# pse84_a0 register map
Vendor: Infineon Technologies; Series: PSE84_A0; File version: 1.0
CPU: CM33 r0p1, little endian, MPU, FPU, VTOR, 3 interrupt priority bits
Registers are 32-bit, read-write, reset 0x0 unless marked. A register's access mark holds for its fields unless they carry their own. Offsets are from the block's base; [hi:lo] are bit positions; lines under a group give offsets from that group; {n}, {i} and the like mark numbered series; 'fields as' and 'values as' point back to an identical list; <NAME> marks a mode.

## USBHS (part 5 of 7) — Regmap for both Subsystem and Controller IP
Base 0x44900000
0x00 DWC_OTG_INTREG group — Internal register map
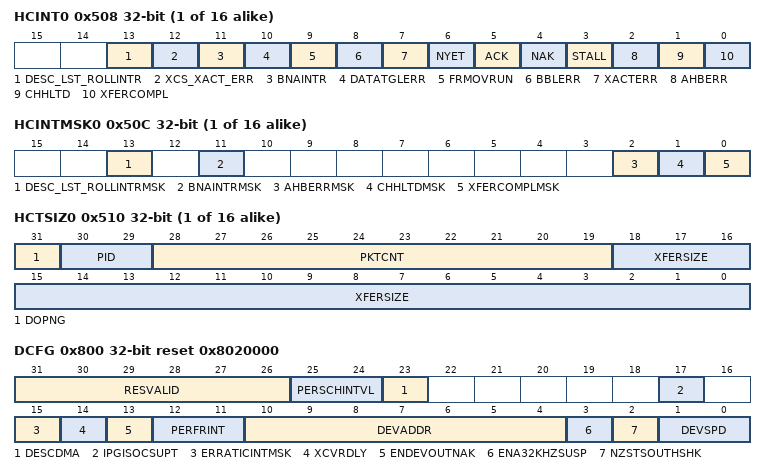
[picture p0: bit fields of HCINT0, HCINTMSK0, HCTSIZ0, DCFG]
  {0x508+0x20*j} HCINT{j} (j=0..15) — This register indicates the status of a channel with respect to USB- and AHB-related events. It is shown in the 'Interrupt Hierarchy' figure in the databook. The application must read this register when the Host Channels Interrupt bit of the Core Interrupt register (GINTSTS.HChInt) is set. Before the application can read this register, it must first read the Host All Channels Interrupt (HAINT) register to get the exact channel number for the Host Channel-n Interrupt register. The application must clear the appropriate bit in this register to clear the corresponding bits in the HAINT and GINTSTS registers.
    [13] DESC_LST_ROLLINTR
      1=ACTIVE (Descriptor rollover interrupt); 0=INACTIVE (No Descriptor rollover interrupt)
    [12] XCS_XACT_ERR
      1=ACTIVE (Excessive Transaction Error); 0=INACTIVE (No Excessive Transaction Error)
    [11] BNAINTR
      1=ACTIVE (BNA Interrupt); 0=INACTIVE (No BNA Interrupt)
    [10] DATATGLERR — Data Toggle Error (DataTglErr).This bit can be set only by the core and the application should write 1 to clear it.In Scatter/Gather DMA mode, the interrupt due to this bit is masked in the core.
      1=ACTIVE (Data Toggle Error); 0=INACTIVE (No Data Toggle Error)
    [9] FRMOVRUN — Frame Overrun (FrmOvrun). In Scatter/Gather DMA mode, the interrupt due to this bit is masked in the core. This bit can be set only by the core and the application should write 1 to clear it.
      1=ACTIVE (Frame Overrun); 0=INACTIVE (No Frame Overrun)
    [8] BBLERR — Babble Error (BblErr) In Scatter/Gather DMA mode, the interrupt due to this bit is masked in the core. This bit can be set only by the core and the application should write 1 to clear it.
      1=ACTIVE (Babble Error); 0=INACTIVE (No Babble Error)
    [7] XACTERR — Transaction Error (XactErr) Indicates one of the following errors occurred on the USB. - CRC check failure - Timeout - Bit stuff error - False EOP In Scatter/Gather DMA mode, the interrupt due to this bit is masked in the core.This bit can be set only by the core and the application should write 1 to clear it.
      1=ACTIVE (Transaction Error); 0=INACTIVE (No Transaction Error)
    [6] NYET — NYET Response Received Interrupt (NYET) In Scatter/Gather DMA mode, the interrupt due to this bit is masked in the core.This bit can be set only by the core and the application should write 1 to clear it.
      1=ACTIVE (NYET Response Received Interrupt); 0=INACTIVE (No NYET Response Received Interrupt)
    [5] ACK — ACK Response Received/Transmitted Interrupt (ACK) In Scatter/Gather DMA mode, the interrupt due to this bit is masked in the core.This bit can be set only by the core and the application should write 1 to clear it.
      1=ACTIVE (ACK Response Received or Transmitted Interrup); 0=INACTIVE (No ACK Response Received or Transmitted Interrupt)
    [4] NAK — NAK Response Received Interrupt (NAK) In Scatter/Gather DMA mode, the interrupt due to this bit is masked in the core.This bit can be set only by the core and the application should write 1 to clear it.
      1=ACTIVE (NAK Response Received Interrupt); 0=INACTIVE (No NAK Response Received Interrupt)
    [3] STALL — STALL Response Received Interrupt (STALL) In Scatter/Gather DMA mode, the interrupt due to this bit is masked in the core.This bit can be set only by the core and the application should write 1 to clear it.
      1=ACTIVE (Stall Response Received Interrupt); 0=INACTIVE (No Stall Response Received Interrupt)
    [2] AHBERR — AHB Error (AHBErr) This is generated only in Internal DMA mode when there is an AHB error during AHB read/write. The application can read the corresponding channel's DMA address register to get the error address. For details, see 'AHB Error Handling' in the Programming Guide.
      1=ACTIVE (AHB error during AHB read/write); 0=INACTIVE (No AHB error)
    [1] CHHLTD — Channel Halted (ChHltd) In non Scatter/Gather DMA mode, it indicates the transfer completed abnormally either because of any USB transaction error or in response to disable request by the application or because of a completed transfer. In Scatter/gather DMA mode, this indicates that transfer completed due to any of the following - EOL being set in descriptor - AHB error - Excessive transaction errors - Babble - Stall
      1=ACTIVE (Channel Halted); 0=INACTIVE (Channel not halted)
    [0] XFERCOMPL — Transfer Completed (XferCompl) Transfer completed normally without any errors.This bit can be set only by the core and the application should write 1 to clear it. - For Scatter/Gather DMA mode, it indicates that current descriptor processing got completed with IOC bit set in its descriptor. - In non Scatter/Gather DMA mode, it indicates that Transfer completed normally without any errors.
      1=ACTIVE (Transfer completed normally without any errors); 0=INACTIVE (Transfer in progress or No Active Transfer)
  {0x50C+0x20*j} HCINTMSK{j} (j=0..15) — This register reflects the mask for each channel status described in the previous section.
    [13] DESC_LST_ROLLINTRMSK — Descriptor List rollover interrupt Mask register(DESC_LST_ROLLIntrMsk) This bit is valid only when Scatter/Gather DMA mode is enabled.
      0=MASK (Descriptor Rollover Interrupt Mask); 1=NOMASK (Descriptor Rollover Interrupt not masked)
    [11] BNAINTRMSK — BNA (Buffer Not Available) Interrupt mask register (BNAIntrMsk) This bit is valid only when Scatter/Gather DMA mode is enabled.
      0=MASK (BNA Interrupt Masked); 1=NOMASK (BNA Interrupt not masked)
    [2] AHBERRMSK — AHB Error Mask (AHBErrMsk) In scatter/gather DMA mode for host, interrupts will not be generated due to the corresponding bits set in HCINTn.
      0=MASK (AHB Error Mask); 1=NOMASK (No AHB Error Mask)
    [1] CHHLTDMSK — Channel Halted Mask (ChHltdMsk)
      0=MASK (Channel Halted Mask); 1=NOMASK (No Channel Halted Mask)
    [0] XFERCOMPLMSK — Transfer Completed Mask (XferComplMsk)
      0=MASK (Transfer Completed Mask); 1=NOMASK (No Transfer Completed Mask)
  {0x510+0x20*j} HCTSIZ{j} (j=0..15) — This register reflects the transfer size for the Host Channel.
    [31] DOPNG — Do Ping (DoPng) This bit is used only for OUT transfers. Setting this field to 1 directs the host to do PING protocol. Note: Do not set this bit for IN transfers. If this bit is set for for IN transfers it disables the channel.
      0=NOPING (No ping protocol); 1=PING (Ping protocol)
    [30:29] PID — PID (Pid) The application programs this field with the type of PID to use for the initial transaction. The host maintains this field for the rest of the transfer. - 2'b00: DATA0 - 2'b01: DATA2 - 2'b10: DATA1 - 2'b11: MDATA (non-control)/SETUP (control)
      0=DATA0; 2=DATA1; 1=DATA2; 3=MDATA (MDATA (non-control)/SETUP (control))
    [28:19] PKTCNT
    [18:0] XFERSIZE
  {0x514+0x20*j} HCDMA{j} (j=0..15) — This register is used by the OTG host in the internal DMA mode to maintain the current buffer pointer for IN/OUT transactions. The starting DMA address must be DWORD-aligned.
    [31:0] DMAADDR
  {0x51C+0x20*j} HCDMAB{j} ro (j=0..15) — This register is present only in case of Scatter/Gather DMA. It is implemented in RAM instead of flop-based implementation. This register holds the current buffer address.
    [31:0] HCDMAB
  0x800 DCFG reset 0x8020000 — This register configures the core in Device mode after power-on or after certain control commands or enumeration. Do not make changes to this register after initial programming.
    [31:26] RESVALID — Resume Validation Period (ResValid) This field is effective only when DCFG.Ena32KHzSusp is set. It controls the resume period when the core resumes from suspend. The core counts for ResValid number of clock cycles to detect a valid resume when this bit is set
    [25:24] PERSCHINTVL
      0=MF25 (25 percent of <ct:DWC_DESIGN_ID==1>frame</ct><ct:DWC_DESIGN_ID!=1>(micro)Frame</ct>); 1=MF50 (50 percent of <ct:DWC_DESIGN_ID==1>frame</ct><ct:DWC_DESIGN_ID!=1>(micro)Frame</ct>); 2=MF75 (75 percent of <ct:DWC_DESIGN_ID==1>frame</ct><ct:DWC_DESIGN_ID!=1>(micro)Frame</ct>); 3=RSVDPerSchIntvlDCFG (N/A)
    [23] DESCDMA — Enable Scatter/gather DMA in device mode (DescDMA). When the Scatter/Gather DMA option selected during configuration of the RTL, the application can Set this bit during initialization to enable the Scatter/Gather DMA operation. Note: This bit must be modified only once after a reset. The following combinations are available for programming: - GAHBCFG.DMAEn=0,DCFG.DescDMA=0 => Slave mode - GAHBCFG.DMAEn=0,DCFG.DescDMA=1 => Invalid - GAHBCFG.DMAEn=1,DCFG.DescDMA=0 => Buffered DMA mode - GAHBCFG.DMAEn=1,DCFG.DescDMA=1 => Scatter/Gather DMA mode
      0=DISABLED (Disable Scatter/Gather DMA); 1=ENABLED (Enable Scatter/Gather DMA)
    [17] IPGISOCSUPT — Worst-Case Inter-Packet Gap ISOC OUT Support (ipgisocSupt) This bit indicates that the controller supports the worst-case scenario of Rx followed by Rx Inter-Packet Gap (IPG) (32 bit times) as per the UTMI Specification for any token following an ISOC OUT token. Without this support, when any token follows an ISOC OUT token with the worst-case IPG, the controller will not detect the followed token. The worst-case IPG of the controller without this support depends on the AHB and PHY clock frequency.
      0=DISABLED (Worst-Case Inter-Packet Gap ISOC OUT Support is disabled); 1=ENABLED (Worst-Case Inter-Packet Gap ISOC OUT Support is enabled)
    [15] ERRATICINTMSK — Erratic Error Interrupt Mask
      1=MASK (Mask early suspend interrupt on erratic error); 0=NOMASK (Early suspend interrupt is generated on erratic error)
    [14] XCVRDLY — XCVRDLY Enables or disables delay between xcvr_sel and txvalid during device chirp
      0=DISABLE (No delay between xcvr_sel and txvalid during Device chirp); 1=ENABLE (Enable delay between xcvr_sel and txvalid during Device chirp)
    [13] ENDEVOUTNAK — Enable Device OUT NAK (EnDevOutNak) This bit enables setting NAK for Bulk OUT endpoints after the transfer is completed for Device mode Descriptor DMA - 1'b0 : The core does not set NAK after Bulk OUT transfer complete - 1'b1 : The core sets NAK after Bulk OUT transfer complete This bit is one time programmable after reset like any other DCFG register bits.
      0=DISABLED (The core does not set NAK after Bulk OUT transfer complete); 1=ENABLED (The core sets NAK after Bulk OUT transfer complete)
    [12:11] PERFRINT — Periodic Frame Interval (PerFrInt) Indicates the time within a (micro)Frame at which the application must be notified using the End Of Periodic Frame Interrupt. This can be used to determine If all the isochronous traffic for that (micro)Frame is complete. - 2'b00: 80 percent of the (micro)Frame interval - 2'b01: 85 percent of the (micro)Frame interval - 2'b10: 90 percent of the (micro)Frame interval - 2'b11: 95 percent of the (micro)Frame interval
      0=EOPF80 (80 percent of the <ct:DWC_DESIGN_ID==1>frame</ct><ct:DWC_DESIGN_ID!=1>(micro)Frame</ct> interval); 1=EOPF85 (85 percent of the <ct:DWC_DESIGN_ID==1>frame</ct><ct:DWC_DESIGN_ID!=1>(micro)Frame</ct> interval); 2=EOPF90 (90 percent of the <ct:DWC_DESIGN_ID==1>frame</ct><ct:DWC_DESIGN_ID!=1>(micro)Frame</ct> interval); 3=EOPF95 (95 percent of the <ct:DWC_DESIGN_ID==1>frame</ct><ct:DWC_DESIGN_ID!=1>(micro)Frame</ct> interval)
    [10:4] DEVADDR — Device Address (DevAddr) The application must program this field after every SetAddress control command.
    [3] ENA32KHZSUSP — Enable 32 KHz Suspend mode (Ena32KHzSusp) This bit can be set only if FS PHY interface is selected. Otherwise, this bit needs to be set to zero. If FS PHY interface is chosen and this bit is set, the PHY clock during Suspend must be switched from 48 MHz to 32 KHz.
      0=DISABLED (USB 1.1 Full-Speed Serial Transceiver not selected); 1=ENABLED (USB 1.1 Full-Speed Serial Transceiver Interface selected)
    [2] NZSTSOUTHSHK — Non-Zero-Length Status OUT Handshake (NZStsOUTHShk) The application can use this field to select the handshake the core sends on receiving a nonzero-length data packet during the OUT transaction of a control transfer's Status stage. - 1'b1: Send a STALL handshake on a nonzero-length status OUT transaction and do not send the received OUT packet to the application. - 1'b0: Send the received OUT packet to the application (zerolength or nonzero-length) and send a handshake based on the NAK and STALL bits for the endpoint in the Device Endpoint Control register.
      0=SENDOUT (Send the received OUT packet to the application (zero-length or non-zero length) and send a handshake based on NAK and STALL bits for the endpoint in the Devce Endpoint Control Register); 1=SENDSTALL (Send a STALL handshake on a nonzero-length status OUT transaction and do not send the received OUT packet to the application)
    [1:0] DEVSPD — Device Speed (DevSpd) Indicates the speed at which the application requires the core to enumerate, or the maximum speed the application can support. However, the actual bus speed is determined only after the connect sequence is completed, and is based on the speed of the USB host to which the core is connected.
      3=USBFS1148 (Full speed USB 1.1 transceiver clock is 48 MHz); 1=USBFS20 (Full speed USB 2.0 PHY clock is 30 MHz or 60 MHz); 0=USBHS20 (High speed USB 2.0 PHY clock is 30 MHz or 60 MHz); 2=USBLS116 (Low speed USB 1.1 transceiver clock is 6 MHz)
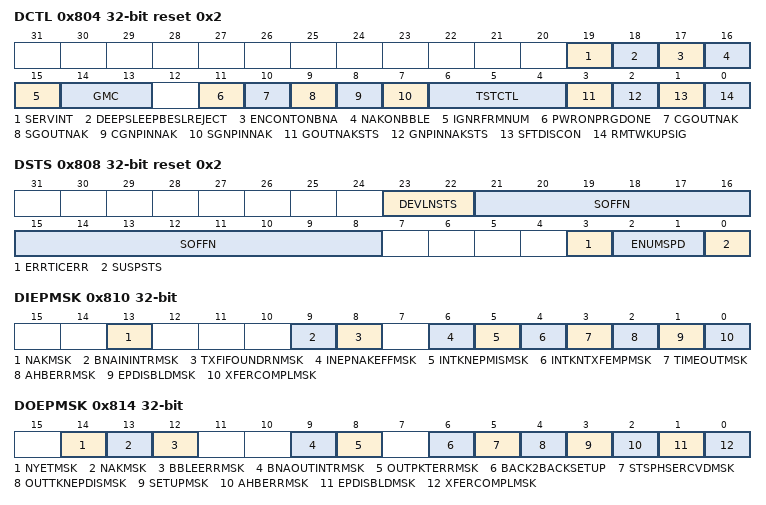
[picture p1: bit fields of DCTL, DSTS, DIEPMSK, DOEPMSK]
  0x804 DCTL reset 0x2 — This register is used to control the characteristics of the Device controller.
    [19] SERVINT — Service Interval based scheduling for Isochronous IN Endpoints This field is used to enable service interval based scheduling feature for ISOC IN EPs. Note: This bit is applicable only in device mode and when Scatter/Gather DMA mode is used. This feature should not be enabled along with DCTL.IgnrFrmNum. Scatter/Gather DMA Mode (GAHBCFG.DMAEn=1,DCFG.DescDMA=1): When this bit is enabled, the frame number field in the ISOC IN descriptor structure is interpreted as the last frame of the service interval. In Scatter/Gather DMA mode, if this bit is enabled, the pending packets are flushed by the controller at the last frame of the service interval.
      0=DISABLED (The controller behavior depends on DCTL.IgnrFrmNum field.); 1=ENABLED (<ct:DWC_DESIGN_ID==0>Scatter/Gather DMA Mode: </ct>The controller can transmit the packets in any frame of the service interval.)
    [18] DEEPSLEEPBESLREJECT — DeepSleepBESLReject - 1: Deep Sleep BESL Reject feature is enabled - 0: Deep Sleep BESL Reject feature is disabled Core rejects LPM request with HIRD value greater than HIRD threshold programmed. NYET response is sent for LPM tokens with HIRD value greater than HIRD threshold. By default, the Deep Sleep BESL Reject feature is disabled.
      0=DISABLED (Deep Sleep BESL Reject feature is disabled); 1=ENABLED (Deep Sleep BESL Reject feature is enabled)
    [17] ENCONTONBNA — Enable Continue on BNA (EnContOnBNA) This bit enables the core to continue on BNA for Bulk OUT endpoints. With this feature enabled, when a Bulk OUT or INTR OUT endpoint receives a BNA interrupt the core starts processing the descriptor that caused the BNA interrupt after the endpoint re-enables the endpoint. - 1'b0: After receiving BNA interrupt,the core disables the endpoint. When the endpoint is re-enabled by the application, the core starts processing from the DOEPDMA descriptor. - 1'b1: After receiving BNA interrupt, the core disables the endpoint. When the endpoint is re-enabled by the application, the core starts processing from the descriptor that received the BNA interrupt. This bit is valid only when OTG_EN_DESC_DMA == 1'b1. It is a one-time programmable after reset bit like any other DCTL register bits.
      0=DISABLED (Core disables the endpoint after receiving BNA interrupt. When application re-enables the endpoint, core starts processing from the DOEPDMA descriptor); 1=ENABLED (Core disables the endpoint after receiving BNA interrupt. When application re-enables the endpoint, core starts processing from the descriptor that received the BNA interrupt.)
    [16] NAKONBBLE — NAK on Babble Error (NakOnBble) Set NAK automatically on babble (NakOnBble). The core sets NAK automatically for the endpoint on which babble is received.
      0=DISABLED (Disable NAK on Babble Error); 1=ENABLED (NAK on Babble Error)
    [15] IGNRFRMNUM — Ignore Frame Number Feature for Isochronous Endpoints (IgnrFrmNum) This field is also used to control the Periodic Transfer Interrupt (PTI) feature. Note: Do not program IgnrFrmNum bit to 1'b1 when the core is operating in threshold mode. Slave Mode (GAHBCFG.DMAEn=0): This bit is not valid in Slave mode and should not be programmed to 1. Scatter/Gather DMA Mode (GAHBCFG.DMAEn=1,DCFG.DescDMA=1): Note: When Scatter/Gather DMA mode is enabled this feature is not applicable to High Speed, High bandwidth transfers. When this bit is enabled, there must be only one packet per descriptor. - 0: The core transmits the packets only in the frame number in which they are intended to be transmitted. - 1: The core ignores the frame number, sending packets immediately as the packets are ready. In Scatter/Gather DMA mode, if this bit is enabled, the packets are not flushed when a ISOC IN token is received for an elapsed frame. Non-Scatter/Gather DMA Mode, that is, Buffer DMA Mode (GAHBCFG.DMAEn=1,DCFG.DescDMA=0): When Scatter/Gather DMA mode is disabled, this field is used by the application to enable Periodic Transfer Interrupt (PTI) Mode. The application can program Periodic Endpoint transfers for multiple (micro)Frames. - 0: Periodic Transfer Interrupt feature is disabled, application needs to program transfers for periodic endpoints every (micro)Frame - 1: Periodic Transfer Interrupt feature is enabled, application can program transfers for multiple (micro)Frames for periodic endpoints. In the PTI mode, the application will receive Transfer Complete Interrupt after transfers for multiple (micro)Frames are completed.
      0=DISABLED (<ct:DWC_DESIGN_ID==0>Scatter/Gather DMA Mode: </ct>The core transmits the packets only in the frame number in which they are intended to be transmitted.<ct:DWC_DESIGN_ID==0><br>Non-Scatter/Gather DMA Mode: Periodic Transfer Interrupt feature is disabled.</ct>); 1=ENABLED (<ct:DWC_DESIGN_ID==0>Scatter/Gather DMA Mode: </ct>The core ignores the frame number, sending packets immediately as the packets are ready.<ct:DWC_DESIGN_ID==0><br>Non-Scatter/Gather DMA Mode: Periodic Transfer Interrupt feature is enabled.</ct>)
    [14:13] GMC
      0=NOTVALID (Invalid); 1=ONEPACKET (1 packet); 3=THREEPACKET (3 packets); 2=TWOPACKET (2 packets)
    [11] PWRONPRGDONE — Power-On Programming Done (PWROnPrgDone) The application uses this bit to indicate that register programming is completed after a wake-up from Power Down mode.
      1=DONE (Power-On Programming Done); 0=NOTDONE (Power-On Programming not done)
    [10] CGOUTNAK wo — Clear Global OUT NAK (CGOUTNak) A write to this field clears the Global OUT NAK.
      0=DISABLED (Disable Clear Global OUT NAK); 1=ENABLED (Clear Global OUT NAK)
    [9] SGOUTNAK wo — Set Global OUT NAK (SGOUTNak) A write to this field sets the Global OUT NAK. The application uses this bit to send a NAK handshake on all OUT endpoints. The application must set the this bit only after making sure that the Global OUT NAK Effective bit in the Core Interrupt Register (GINTSTS.GOUTNakEff) is cleared.
      0=DISABLED (Disable Global OUT NAK); 1=ENABLED (Set Global OUT NAK)
    [8] CGNPINNAK wo — Clear Global Non-periodic IN NAK (CGNPInNak) A write to this field clears the Global Non-periodic IN NAK.
      0=DISABLE (Disable Global Non-periodic IN NAK); 1=ENABLE (Clear Global Non-periodic IN NAK)
    [7] SGNPINNAK wo — Set Global Non-periodic IN NAK (SGNPInNak) A write to this field sets the Global Non-periodic IN NAK.The application uses this bit to send a NAK handshake on all non-periodic IN endpoints. The core can also Set this bit when a timeout condition is detected on a non-periodic endpoint in shared FIFO operation. The application must Set this bit only after making sure that the Global IN NAK Effective bit in the Core Interrupt Register (GINTSTS.GINNakEff) is cleared
      0=DISABLE (Disable Global Non-periodic IN NAK); 1=ENABLE (Set Global Non-periodic IN NAK)
    [6:4] TSTCTL
      0=DISABLED (Test mode disabled); 5=TESTFE (Test_force_Enable); 1=TESTJ (Test_J mode); 2=TESTK (Test_K mode); 4=TESTPM (Test_Packet mode); 3=TESTSN (Test_SE0_NAK mode)
    [3] GOUTNAKSTS ro — Global OUT NAK Status (GOUTNakSts) - 1'b0: A handshake is sent based on the FIFO Status and the NAK and STALL bit settings. - 1'b1: No data is written to the RxFIFO, irrespective of space availability. Sends a NAK handshake on all packets, except on SETUP transactions. All isochronous OUT packets are dropped.
      1=ACTIVE (No data is written to the RxFIFO, irrespective of space availability. Sends a NAK handshake on all packets, except on SETUP transactions. All isochronous OUT packets are dropped.); 0=INACTIVE (A handshake is sent based on the FIFO Status and the NAK and STALL bit settings.)
    [2] GNPINNAKSTS ro — Global Non-periodic IN NAK Status (GNPINNakSts) - 1'b0: A handshake is sent out based on the data availability in the transmit FIFO. - 1'b1: A NAK handshake is sent out on all non-periodic IN endpoints, irrespective of the data availability in the transmit FIFO.
      1=ACTIVE (A NAK handshake is sent out on all non-periodic IN endpoints, irrespective of the data availability in the transmit FIFO.); 0=INACTIVE (A handshake is sent out based on the data availability in the transmit FIFO)
    [1] SFTDISCON — Soft Disconnect (SftDiscon) The application uses this bit to signal the controller to do a soft disconnect. As long as this bit is set, the host does not see that the device is connected, and the device does not receive signals on the USB. The core stays in the disconnected state until the application clears this bit. - 1'b0: Normal operation. When this bit is cleared after a soft disconnect, the core drives the phy_opmode_o signal on the UTMI+ to 2'b00, which generates a device connect event to the USB host. When the device is reconnected, the USB host restarts device enumeration. - 1'b1: The core drives the phy_opmode_o signal on the UTMI+ to 2'b01, which generates a device disconnect event to the USB host. The following is the minimum duration under various conditions for which this bit must be set for the USB host to detect a device disconnect. To accommodate clock jitter, it is recommended that the application adds some extra delay to the specified minimum duration. For high speed, if the device state is, - Suspended, the minimum duration is 1ms + 2.5us - Idle, the minimum duration is 3ms + 2.5us - Not Idle or Suspended (performing transactions), the minimum duration 125 us For full speed/low speed, if the device state is, - Suspended, the minimum duration is 1ms + 2.5us - Idle, the minimum duration is 2.5us - Not Idle or Suspended (performing transactions), the minimum duration 125 us Note: - This bit can be also used for ULPI/FS Serial interfaces. - This bit is not impacted by a soft reset.
      1=DISCONNECT (The core <ct:DWC_DESIGN_ID!=1>drives the phy_opmode_o signal on the UTMI+ to 2'b01, which </ct>generates a device disconnect event to the USB host); 0=NODISCONNECT (The core <ct:DWC_DESIGN_ID!=1>drives the phy_opmode_o signal on the UTMI+ to 2'b00, which </ct>generates a device connect event to the USB host)
    [0] RMTWKUPSIG — Remote Wakeup Signaling (RmtWkUpSig) When the application sets this bit, the core initiates remote signaling to wake up the USB host. The application must Set this bit to instruct the core to exit the Suspend state. As specified in the USB 2.0 specification, the application must clear this bit 1-15 ms after setting it. If LPM is enabled and the core is in the L1 (Sleep) state, when the application sets this bit, the core initiates L1 remote signaling to wake up the USB host. The application must set this bit to instruct the core to exit the Sleep state. As specified in the LPM specification, the hardware automatically clears this bit 50 microseconds (TL1DevDrvResume) after being set by the application. The application must not set this bit when GLPMCFG bRemoteWake from the previous LPM transaction is zero.
      0=DISABLEDRMWKUP (Core does not send Remote Wakeup Signaling); 1=ENABLERMWKUP (Core sends Remote Wakeup Signaling)
  0x808 DSTS ro reset 0x2 — This register indicates the status of the core with respect to USB-related events. It must be read on interrupts from Device All Interrupts (DAINT) register.
    [23:22] DEVLNSTS — Device Line Status (DevLnSts) Indicates the current logic level USB data lines - DevLnSts[1]: Logic level of D+ - DevLnSts[0]: Logic level of D-
    [21:8] SOFFN — Frame or Microframe Number of the Received SOF (SOFFN) When the core is operating at high speed, this field contains a microframe number. When the core is operating at full or low speed, this field contains a Frame number. Note: This register may return a non-zero value if read immediately after power-on reset. In case the register bit reads non-zero immediately after power-on reset, it does not indicate that SOF has been received from the host. The read value of this interrupt is valid only after a valid connection between host and device is established.
    [3] ERRTICERR — Erratic Error (ErrticErr) The core sets this bit to report any erratic errors (phy_rxvalid_i/phy_rxvldh_i or phy_rxactive_i is asserted for at least 2 ms, due to PHY error) seen on the UTMI+. Due to erratic errors, the core goes into Suspended state and an interrupt is generated to the application with Early Suspend bit of the Core Interrupt register (GINTSTS.ErlySusp). If the early suspend is asserted due to an erratic error, the application can only perform a soft disconnect recover.
      1=ACTIVE (Erratic Error); 0=INACTIVE (No Erratic Error)
    [2:1] ENUMSPD — Enumerated Speed (EnumSpd) Indicates the speed at which the controller has come up after speed detection through a connect or reset sequence. - 2'b00: High speed (PHY clock is running at 30 or 60 MHz) - 2'b01: Full speed (PHY clock is running at 30 or 60 MHz) - 2'b10: Low speed (PHY clock is running at 6 MHz) - 2'b11: Full speed (PHY clock is running at 48 MHz) Low speed is not supported for devices using a UTMI+ PHY.
      1=FS3060 (Full speed (PHY clock is running at 30 or 60 MHz)); 3=FS48 (Full speed (PHY clock is running at 48 MHz)); 0=HS3060 (High speed (PHY clock is running at 30 or 60 MHz)); 2=LS6 (Low speed (PHY clock is running at 6 MHz))
    [0] SUSPSTS — Suspend Status (SuspSts) In Device mode, this bit is set as long as a Suspend condition is detected on the USB. The core enters the Suspend state when there is no activity on the phy_line_state_i signal for an extended period of time. The core comes out of the suspend under the following conditions : - If there is any activity on the phy_line_state_i signal, or - If the application writes to the Remote Wakeup Signaling bit in the Device Control register (DCTL.RmtWkUpSig). When the core comes out of the suspend, this bit is set to 1'b0.
      1=ACTIVE (Suspend state); 0=INACTIVE (No suspend state)
  0x810 DIEPMSK — This register works with each of the Device IN Endpoint Interrupt (DIEPINTn) registers for all endpoints to generate an interrupt per IN endpoint. The IN endpoint interrupt for a specific status in the DIEPINTn register can be masked by writing to the corresponding bit in this register. Status bits are masked by default.
    [13] NAKMSK — NAK interrupt Mask (NAKMsk)
      0=MASK (Mask NAK Interrupt); 1=NOMASK (No Mask NAK Interrupt)
    [9] BNAININTRMSK — BNA interrupt Mask (BNAInIntrMsk)
      0=MASK (Mask BNA Interrupt); 1=NOMASK (No BNA Interrupt Mask)
    [8] TXFIFOUNDRNMSK — Fifo Underrun Mask (TxfifoUndrnMsk)
      0=MASK (Mask Fifo Underrun Interrupt); 1=NOMASK (No Fifo Underrun Interrupt Mask)
    [6] INEPNAKEFFMSK — IN Endpoint NAK Effective Mask (INEPNakEffMsk)
      0=MASK (Mask IN Endpoint NAK Effective Interrupt); 1=NOMASK (No IN Endpoint NAK Effective Interrupt Mask)
    [5] INTKNEPMISMSK — IN Token received with EP Mismatch Mask (INTknEPMisMsk)
      0=MASK (Mask IN Token received with EP Mismatch Interrupt); 1=NOMASK (No Mask IN Token received with EP Mismatch Interrupt)
    [4] INTKNTXFEMPMSK — IN Token Received When TxFIFO Empty Mask (INTknTXFEmpMsk)
      0=MASK (Mask IN Token Received When TxFIFO Empty Interrupt); 1=NOMASK (No IN Token Received When TxFIFO Empty Interrupt)
    [3] TIMEOUTMSK — Timeout Condition Mask (TimeOUTMsk) (Non-isochronous endpoints)
      0=MASK (Mask Timeout Condition Interrupt); 1=NOMASK (No Timeout Condition Interrupt Mask)
    [2] AHBERRMSK — AHB Error Mask (AHBErrMsk)
      0=MASK (Mask AHB Error Interrupt); 1=NOMASK (No AHB Error Interrupt Mask)
    [1] EPDISBLDMSK — Endpoint Disabled Interrupt Mask (EPDisbldMsk)
      0=MASK (Mask Endpoint Disabled Interrupt); 1=NOMASK (No Endpoint Disabled Interrupt Mask)
    [0] XFERCOMPLMSK — Transfer Completed Interrupt Mask (XferComplMsk)
      0=MASK (Mask Transfer Completed Interrupt); 1=NOMASK (No Transfer Completed Interrupt Mask)
  0x814 DOEPMSK — This register works with each of the Device OUT Endpoint Interrupt (DOEPINTn) registers for all endpoints to generate an interrupt per OUT endpoint. The OUT endpoint interrupt for a specific status in the DOEPINTn register can be masked by writing into the corresponding bit in this register. Status bits are masked by default.
    [14] NYETMSK — NYET interrupt Mask (NYETMsk)
      0=MASK (Mask NYET Interrupt); 1=NOMASK (No NYET Interrupt Mask)
    [13] NAKMSK — NAK interrupt Mask (NAKMsk)
      0=MASK (Mask NAK Interrupt); 1=NOMASK (No NAK Interrupt Mask)
    [12] BBLEERRMSK — Babble Error interrupt Mask (BbleErrMsk)
      0=MASK (Mask Babble Error Interrupt); 1=NOMASK (No Babble Error Interrupt Mask)
    [9] BNAOUTINTRMSK — BNA interrupt Mask (BnaOutIntrMsk)
      values as DWC_OTG_INTREG.DIEPMSK.BNAININTRMSK
    [8] OUTPKTERRMSK — OUT Packet Error Mask (OutPktErrMsk)
      0=MASK (Mask OUT Packet Error Interrupt); 1=NOMASK (No OUT Packet Error Interrupt Mask)
    [6] BACK2BACKSETUP — Back-to-Back SETUP Packets Received Mask (Back2BackSETup) Applies to control OUT endpoints only.
      0=MASK (Mask Back-to-Back SETUP Packets Received Interrupt); 1=NOMASK (No Back-to-Back SETUP Packets Received Interrupt Mask)
    [5] STSPHSERCVDMSK — Status Phase Received Mask (StsPhseRcvdMsk) Applies to control OUT endpoints only.
      0=MASK (Status Phase Received Mask); 1=NOMASK (No Status Phase Received Mask)
    [4] OUTTKNEPDISMSK — OUT Token Received when Endpoint Disabled Mask (OUTTknEPdisMsk) Applies to control OUT endpoints only.
      0=MASK (Mask OUT Token Received when Endpoint Disabled Interrupt); 1=NOMASK (No OUT Token Received when Endpoint Disabled Interrupt Mask)
    [3] SETUPMSK — SETUP Phase Done Mask (SetUPMsk) Applies to control endpoints only.
      0=MASK (Mask SETUP Phase Done Interrupt); 1=NOMASK (No SETUP Phase Done Interrupt Mask)
    [2] AHBERRMSK — AHB Error (AHBErrMsk)
      values as DWC_OTG_INTREG.DIEPMSK.AHBERRMSK
    [1] EPDISBLDMSK — Endpoint Disabled Interrupt Mask (EPDisbldMsk)
      values as DWC_OTG_INTREG.DIEPMSK.EPDISBLDMSK
    [0] XFERCOMPLMSK — Transfer Completed Interrupt Mask (XferComplMsk)
      values as DWC_OTG_INTREG.DIEPMSK.XFERCOMPLMSK
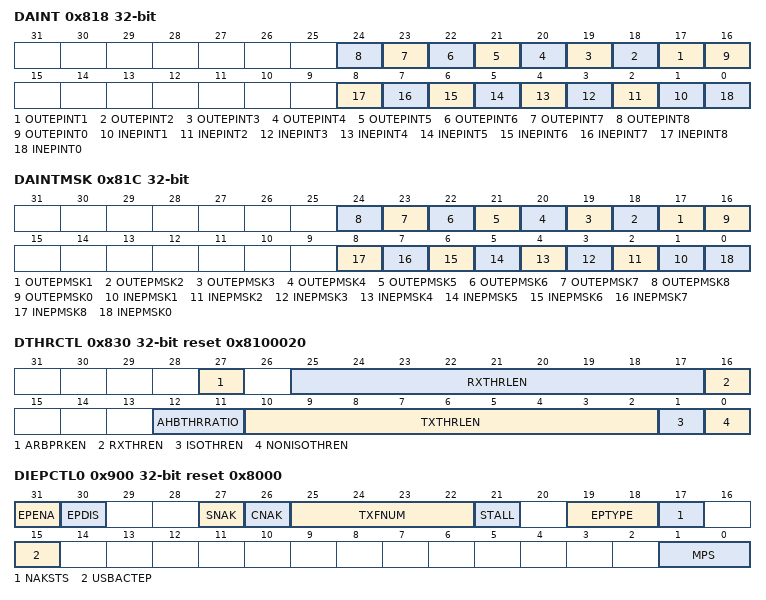
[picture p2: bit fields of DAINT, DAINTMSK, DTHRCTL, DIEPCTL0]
  0x818 DAINT ro — When a significant event occurs on an endpoint, a Device All Endpoints Interrupt register interrupts the application using the Device OUT Endpoints Interrupt bit or Device IN Endpoints Interrupt bit of the Core Interrupt register (GINTSTS.OEPInt or GINTSTS.IEPInt, respectively). This is shown in Figure 5-2. There is one interrupt bit per endpoint, up to a maximum of 16 bits for OUT endpoints and 16 bits for IN endpoints. For a bidirectional endpoint, the corresponding IN and OUT interrupt bits are used. Bits in this register are set and cleared when the application sets and clears bits in the corresponding Device Endpoint-n Interrupt register (DIEPINTn/DOEPINTn).
    [n+16] OUTEPINT{n} (n=1..8) — OUT Endpoint {n} Interrupt Bit
      1=ACTIVE (Interrupt is active for the OUT EP); 0=INACTIVE (No Interrupt)
    [16] OUTEPINT0 — OUT Endpoint 0 Interrupt Bit
      1=ACTIVE (Interrupt is active for OUT EP0); 0=INACTIVE (No Interrupt)
    [n] INEPINT{n} (n=1..8) — IN Endpoint {n} Interrupt Bit
      1=ACTIVE (Interrupt is active for the IN EP); 0=INACTIVE (No Interrupt)
    [0] INEPINT0 — IN Endpoint 0 Interrupt Bit
      1=ACTIVE (Interrupt is active for IN EP0); 0=INACTIVE (No Interrupt)
  0x81C DAINTMSK — The Device Endpoint Interrupt Mask register works with the Device Endpoint Interrupt register to interrupt the application when an event occurs on a device endpoint. However, the Device All Endpoints Interrupt (DAINT) register bit corresponding to that interrupt is still set.
    [n+16] OUTEPMSK{n} (n=1..8) — OUT Endpoint {n} Interrupt mask Bit
      0=MASK (Mask OUT Endpoint Interrupt); 1=NOMASK (No Interrupt mask)
    [16] OUTEPMSK0 — OUT Endpoint 0 Interrupt mask Bit
      0=MASK (Mask OUT Endpoint 0 Interrupt); 1=NOMASK (No Interrupt mask)
    [n] INEPMSK{n} (n=1..8) — IN Endpoint {n} Interrupt mask Bit
      0=MASK (Mask IN Endpoint Interrupt); 1=NOMASK (No Interrupt mask)
    [0] INEPMSK0 — IN Endpoint 0 Interrupt mask Bit
      0=MASK (Mask IN Endpoint 0 Interrupt); 1=NOMASK (No Interrupt mask)
  0x828 DVBUSDIS reset 0x17D7 — This register specifies the VBUS discharge time after VBUS pulsing during SRP.
    [15:0] DVBUSDIS — Device VBUS Discharge Time (DVBUSDis) Specifies the VBUS discharge time after VBUS pulsing during SRP. This value equals (VBUS discharge time in PHY clocks) / 1, 024. The value you use depends whether the PHY is operating at 30MHz (16-bit data width) or 60 MHz (8-bit data width). Depending on your VBUS load, this value can need adjustment.
  0x82C DVBUSPULSE reset 0x5B8 — This register contains the VBUS pulsing time during SRP.
    [11:0] DVBUSPULSE — Device VBUS Pulsing Time (DVBUSPulse) Specifies the VBUS pulsing time during SRP. This value equals (VBUS pulsing time in PHY clocks) / 1, 024 The value you use depends whether the PHY is operating at 30MHz (16-bit data width) or 60 MHz (8-bit data width).
  0x830 DTHRCTL reset 0x8100020 — This register contains the Receive and Transmit Threshold characteristics of the Device controller.
    [27] ARBPRKEN — Arbiter Parking Enable (ArbPrkEn) This bit controls internal DMA arbiter parking for IN endpoints. If thresholding is enabled and this bit is set to one, then the arbiter parks on the IN endpoint for which there is a token received on the USB. This is done to avoid getting into underrun conditions. By default, arbiter parking is enabled.
      0=DISABLED (Disable DMA arbiter parking); 1=ENABLED (Enable DMA arbiter parking for IN endpoints)
    [25:17] RXTHRLEN — Receive Threshold Length (RxThrLen) This field specifies Receive thresholding size in DWORDS. This field also specifies the amount of data received on the USB before the core can start transmitting on the AHB. The threshold length has to be at least eight DWORDS. The recommended value for ThrLen is to be the same as the programmed AHB Burst Length (GAHBCFG.HBstLen).
    [16] RXTHREN — Receive Threshold Enable (RxThrEn) When this bit is set, the core enables thresholding in the receive direction. Note: We recommends that you do not enable RxThrEn, because it may cause issues in the RxFIFO especially during error conditions such as RxError and Babble.
      0=DISABLED (Disable thresholding); 1=ENABLED (Enable thresholding in the receive direction)
    [12:11] AHBTHRRATIO — AHB Threshold Ratio (AHBThrRatio) These bits define the ratio between the AHB threshold and the MAC threshold for the transmit path only. The AHB threshold always remains less than or equal to the USB threshold, because this does not increase overhead. Both the AHB and the MAC threshold must be DWORD-aligned. The application needs to program TxThrLen and the AHBThrRatio to make the AHB Threshold value DWORD aligned. If the AHB threshold value is not DWORD aligned, the core might not behave correctly. When programming the TxThrLen and AHBThrRatio, the application must ensure that the minimum AHB threshold value does not go below 8 DWORDS to meet the USB turnaround time requirements. - 2'b00: AHB threshold = MAC threshold - 2'b01: AHB threshold = MAC threshold / 2 - 2'b10: AHB threshold = MAC threshold / 4 - 2'b11: AHB threshold = MAC threshold / 8
      1=THRESONE (AHB threshold = MAC threshold /2); 3=THRESTHREE (AHB threshold = MAC threshold /8); 2=THRESTWO (AHB threshold = MAC threshold /4); 0=THRESZERO (AHB threshold = MAC threshold)
    [10:2] TXTHRLEN — Transmit Threshold Length (TxThrLen) This field specifies Transmit thresholding size in DWORDS. This also forms the MAC threshold and specifies the amount of data in bytes to be in the corresponding endpoint transmit FIFO, before the core can start transmit on the USB. The threshold length has to be at least eight DWORDS when the value of AHBThrRatio is 2'h00. In case the AHBThrRatio is non zero the application needs to ensure that the AHB Threshold value does not go below the recommended eight DWORD. This field controls both isochronous and non-isochronous IN endpoint thresholds. The recommended value for ThrLen is to be the same as the programmed AHB Burst Length (GAHBCFG.HBstLen). Note: - When OTG_ARCHITECTURE=0, the reset value of this register field is 0. - When OTG_ARCHITECTURE=2, the reset value of this register field is 8.
    [1] ISOTHREN — ISO IN Endpoints Threshold Enable. (ISOThrEn) When this bit is Set, the core enables thresholding for isochronous IN endpoints.
      0=DISABLED (No thresholding); 1=ENABLED (Enables thresholding for isochronous IN endpoints)
    [0] NONISOTHREN — Non-ISO IN Endpoints Threshold Enable. (NonISOThrEn) When this bit is Set, the core enables thresholding for Non Isochronous IN endpoints.
      0=DISABLED (No thresholding); 1=ENABLED (Enable thresholding for non-isochronous IN endpoints)
  0x834 DIEPEMPMSK — This register is valid only in Dedicated FIFO operation (OTG_EN_DED_TX_FIFO = 1). This register is used to control the IN endpoint FIFO empty interrupt generation (DIEPINTn.TxfEmp).
    [15:0] INEPTXFEMPMSK — IN EP Tx FIFO Empty Interrupt Mask Bits (InEpTxfEmpMsk) These bits acts as mask bits for DIEPINTn.TxFEmp interrupt, one bit per IN Endpoint: Bit 0 for IN EP 0, bit 15 for IN EP 15
  0x900 DIEPCTL0 reset 0x8000 — This register is used to control the characteristics of the IN Endpoint 0 of the Device controller.
    [31] EPENA — Endpoint Enable (EPEna) When Scatter/Gather DMA mode is enabled for IN endpoints, this bit indicates that the descriptor structure and data buffer with data ready to transmit is setup. When Scatter/Gather DMA mode is disabled (such as in buffer pointer based DMA mode) this bit indicates that data is ready to be transmitted on the endpoint. The core clears this bit before setting the following interrupts on this endpoint: - Endpoint Disabled - Transfer Completed
      1=ACTIVE (Enable Endpoint); 0=INACTIVE (No action)
    [30] EPDIS — Endpoint Disable (EPDis) The application sets this bit to stop transmitting data on an endpoint, even before the transfer for that endpoint is complete. The application must wait for the Endpoint Disabled interrupt before treating the endpoint as disabled. The core clears this bit before setting the Endpoint Disabled Interrupt. The application must Set this bit only if Endpoint Enable is already set for this endpoint.
      1=ACTIVE (Disabled Endpoint); 0=INACTIVE (No action)
    [27] SNAK wo — Set NAK (SNAK) A write to this bit sets the NAK bit for the endpoint. Using this bit, the application can control the transmission of NAK handshakes on an endpoint. The core can also set this bit for an endpoint after a SETUP packet is received on that endpoint.
      0=NOSET (No action); 1=SET (Set NAK)
    [26] CNAK wo — Clear NAK (CNAK) A write to this bit clears the NAK bit for the endpoint.
      1=CLEAR (Clear NAK); 0=NOCLEAR (No action)
    [25:22] TXFNUM — TxFIFO Number (TxFNum) - For Shared FIFO operation, this value is always set to 0, indicating that control IN endpoint 0 data is always written in the Non-Periodic Transmit FIFO. - For Dedicated FIFO operation, this value is set to the FIFO number that is assigned to IN Endpoint.
      {v}=TXFIFO{v} (v=0..15)
    [21] STALL — STALL Handshake (Stall) The application can only set this bit, and the core clears it, when a SETUP token is received for this endpoint. If a NAK bit, Global Nonperiodic IN NAK, or Global OUT NAK is set along with this bit, the STALL bit takes priority.
      1=ACTIVE (Stall Handshake); 0=INACTIVE (No Stall)
    [19:18] EPTYPE ro — Endpoint Type (EPType) Hardcoded to 00 for control.
      0=ACTIVE (Endpoint Control 0)
    [17] NAKSTS ro — NAK Status (NAKSts) Indicates the following: - 1'b0: The core is transmitting non-NAK handshakes based on the FIFO status - 1'b1: The core is transmitting NAK handshakes on this endpoint. When this bit is set, either by the application or core, the core stops transmitting data, even If there is data available in the TxFIFO. Irrespective of this bit's setting, the core always responds to SETUP data packets with an ACK handshake.
      1=ACTIVE (The core is transmitting NAK handshakes on this endpoint); 0=INACTIVE (The core is transmitting non-NAK handshakes based on the FIFO status)
    [15] USBACTEP ro — USB Active Endpoint (USBActEP) This bit is always SET to 1, indicating that control endpoint 0 is always active in all configurations and interfaces.
      1=ACTIVE0 (Control endpoint is always active)
    [1:0] MPS — Maximum Packet Size (MPS) Applies to IN and OUT endpoints. The application must program this field with the maximum packet size for the current logical endpoint. - 2'b00: 64 bytes - 2'b01: 32 bytes - 2'b10: 16 bytes - 2'b11: 8 bytes
      2=BYTES16 (16 bytes); 1=BYTES32 (32 bytes); 0=BYTES64 (64 bytes); 3=BYTES8 (8 bytes)
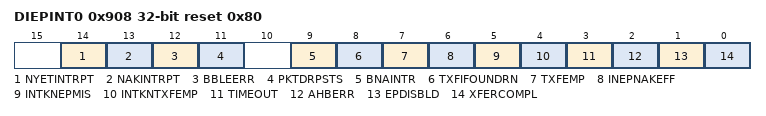
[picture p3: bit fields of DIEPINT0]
  0x908 DIEPINT0 reset 0x80 — This register indicates the status of an endpoint with respect to USB- and AHB-related events. It is shown in the 'Interrupt Hierarchy' figure in the databook. The application must read this register when the OUT Endpoints Interrupt bit or IN Endpoints Interrupt bit of the Core Interrupt register (GINTSTS.OEPInt or GINTSTS.IEPInt, respectively) is set. Before the application can read this register, it must first read the Device All Endpoints Interrupt (DAINT) register to get the exact endpoint number for the Device Endpoint-n Interrupt register. The application must clear the appropriate bit in this register to clear the corresponding bits in the DAINT and GINTSTS registers
    [14] NYETINTRPT — NYET Interrupt (NYETIntrpt) The core generates this interrupt when a NYET response is transmitted for a non isochronous OUT endpoint.
      1=ACTIVE (NYET Interrupt); 0=INACTIVE (No interrupt)
    [13] NAKINTRPT — NAK Interrupt (NAKInterrupt) The core generates this interrupt when a NAK is transmitted or received by the device. <brIn case of isochronous IN endpoints the interrupt gets generated when a zero length packet is transmitted due to un-availability of data in the TXFifo.
      1=ACTIVE (NAK Interrupt); 0=INACTIVE (No interrupt)
    [12] BBLEERR — NAK Interrupt (BbleErr) The core generates this interrupt when babble is received for the endpoint.
      1=ACTIVE (BbleErr interrupt); 0=INACTIVE (No interrupt)
    [11] PKTDRPSTS — Packet Drop Status (PktDrpSts) This bit indicates to the application that an ISOC OUT packet has been dropped. This bit does not have an associated mask bit and does not generate an interrupt. Dependency: This bit is valid in non Scatter/Gather DMA mode when periodic transfer interrupt feature is selected.
      1=ACTIVE (Packet Drop Status); 0=INACTIVE (No interrupt)
    [9] BNAINTR — BNA (Buffer Not Available) Interrupt (BNAIntr) This bit is valid only when Scatter/Gather DMA mode is enabled. The core generates this interrupt when the descriptor accessed is not ready for the Core to process, such as Host busy or DMA done.
      1=ACTIVE (BNA interrupt); 0=INACTIVE (No BNA interrupt)
    [8] TXFIFOUNDRN — Fifo Underrun (TxfifoUndrn) Applies to IN endpoints only. The core generates this interrupt when it detects a transmit FIFO underrun condition in threshold mode for this endpoint.
      1=ACTIVE (Fifo Underrun interrupt); 0=INACTIVE (No Fifo Underrun interrupt)
    [7] TXFEMP ro — Transmit FIFO Empty (TxFEmp) This bit is valid only for IN Endpoints This interrupt is asserted when the TxFIFO for this endpoint is either half or completely empty. The half or completely empty status is determined by the TxFIFO Empty Level bit in the Core AHB Configuration register (GAHBCFG.NPTxFEmpLvl)).
      1=ACTIVE (Transmit FIFO Empty interrupt); 0=INACTIVE (No Transmit FIFO Empty interrupt)
    [6] INEPNAKEFF — IN Endpoint NAK Effective (INEPNakEff) Applies to periodic IN endpoints only. This bit can be cleared when the application clears the IN endpoint NAK by writing to DIEPCTLn.CNAK. This interrupt indicates that the core has sampled the NAK bit Set (either by the application or by the core). The interrupt indicates that the IN endpoint NAK bit Set by the application has taken effect in the core. This interrupt does not guarantee that a NAK handshake is sent on the USB. A STALL bit takes priority over a NAK bit.
      1=ACTIVE (IN Endpoint NAK Effective interrupt); 0=INACTIVE (No IN Endpoint NAK Effective interrupt)
    [5] INTKNEPMIS — IN Token Received with EP Mismatch (INTknEPMis) Applies to non-periodic IN endpoints only. Indicates that the data in the top of the non-periodic TxFIFO belongs to an endpoint other than the one for which the IN token was received. This interrupt is asserted on the endpoint for which the IN token was received.
      1=ACTIVE (IN Token Received with EP Mismatch interrupt); 0=INACTIVE (No IN Token Received with EP Mismatch interrupt)
    [4] INTKNTXFEMP — IN Token Received When TxFIFO is Empty (INTknTXFEmp) Applies to non-periodic IN endpoints only. Indicates that an IN token was received when the associated TxFIFO (periodic/non-periodic) was empty. This interrupt is asserted on the endpoint for which the IN token was received.
      1=ACTIVE (IN Token Received when TxFIFO Empty Interrupt); 0=INACTIVE (No IN Token Received when TxFIFO Empty interrupt)
    [3] TIMEOUT — Timeout Condition (TimeOUT) - In shared TX FIFO mode, applies to non-isochronous IN endpoints only. - In dedicated FIFO mode, applies only to Control IN endpoints. - In Scatter/Gather DMA mode, the TimeOUT interrupt is not asserted. Indicates that the core has detected a timeout condition on the USB for the last IN token on this endpoint.
      1=ACTIVE (Timeout interrupt); 0=INACTIVE (No Timeout interrupt)
    [2] AHBERR — AHB Error (AHBErr) Applies to IN and OUT endpoints. This is generated only in Internal DMA mode when there is an AHB error during an AHB read/write. The application can read the corresponding endpoint DMA address register to get the error address. For details, see 'AHB Error Handling' in the Programming Guide.
      1=ACTIVE (AHB Error interrupt); 0=INACTIVE (No AHB Error Interrupt)
    [1] EPDISBLD — Endpoint Disabled Interrupt (EPDisbld) Applies to IN and OUT endpoints. This bit indicates that the endpoint is disabled per the application's request.
      1=ACTIVE (Endpoint Disabled Interrupt); 0=INACTIVE (No Endpoint Disabled Interrupt)
    [0] XFERCOMPL — Transfer Completed Interrupt (XferCompl) Applies to IN and OUT endpoints. - When Scatter/Gather DMA mode is enabled -- For IN endpoint this field indicates that the requested data from the descriptor is moved from external system memory to internal FIFO. -- For OUT endpoint this field indicates that the requested data from the internal FIFO is moved to external system memory. This interrupt is generated only when the corresponding endpoint descriptor is closed, and the IOC bit for the corresponding descriptor is set. - When Scatter/Gather DMA mode is disabled, this field indicates that the programmed transfer is complete on the AHB as well as on the USB, for this endpoint.
      1=ACTIVE (Transfer Completed Interrupt); 0=INACTIVE (No Transfer Complete Interrupt)
